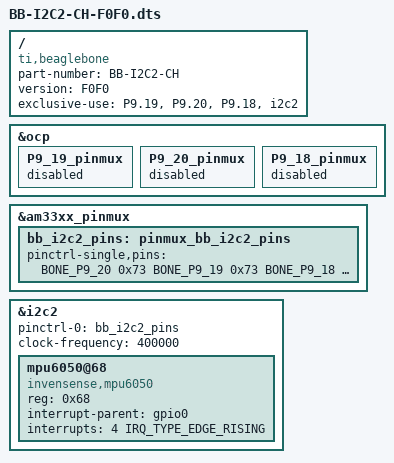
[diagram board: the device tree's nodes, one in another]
/*
 * Copyright (C) 2013 CircuitCo
 *
 * Virtual cape for I2C2 on connector pins P9.19 P9.20
 *
 * This program is free software; you can redistribute it and/or modify
 * it under the terms of the GNU General Public License version 2 as
 * published by the Free Software Foundation.
 */

/dts-v1/;
/plugin/;

#include <dt-bindings/interrupt-controller/irq.h>
#include <dt-bindings/board/am335x-bbw-bbb-base.h>
#include <dt-bindings/pinctrl/am33xx.h>

/ {
	compatible = "ti,beaglebone", "ti,beaglebone-black", "ti,beaglebone-green";

	// identification
	part-number = "BB-I2C2-CH";
	version = "F0F0";

	// resources this cape uses
	exclusive-use =
		"P9.19",	// i2c2_scl
		"P9.20",	// i2c2_sda
		"P9.18",	// int
		
		"i2c2";		// hardware ip used

	/*
	 * Free up the pins used by the cape from the pinmux helpers.
	 */
	fragment@0 {
		target = <&ocp>;
		__overlay__ {
			P9_19_pinmux { status = "disabled"; };	/* i2c2_scl */
			P9_20_pinmux { status = "disabled"; };	/* i2c2_sda */
			P9_18_pinmux { status = "disabled"; };	/*int	*/
		};
	};

	fragment@1 {
		target = <&am33xx_pinmux>;
		__overlay__ {
			bb_i2c2_pins: pinmux_bb_i2c2_pins {
				pinctrl-single,pins = <
					BONE_P9_20 0x73	/* i2c2_sda, SLEWCTRL_SLOW | INPUT_PULLUP | MODE3 */
					BONE_P9_19 0x73	/* i2c2_scl, SLEWCTRL_SLOW | INPUT_PULLUP | MODE3 */
					BONE_P9_18 0x0F	/* INT,		 SLEWCTRL_SLOW | iNPUT_NULL	  | MODE7 */
				>;
			};
		};
	};

	fragment@2 {
		target = <&i2c2>;
		__overlay__ {
			status = "okay";
			pinctrl-names = "default";
			pinctrl-0 = <&bb_i2c2_pins>;

			/* this is the configuration part */
			clock-frequency = <400000>;

			#address-cells = <1>;
			#size-cells = <0>;

			/* add any i2c devices on the bus here */

			mpu6050@68 {
				compatible = "invensense,mpu6050";
				reg = <0x68>;
				interrupt-parent = <&gpio0>;
				interrupts = <4 IRQ_TYPE_EDGE_RISING>;
			};

                        //hmc5883l@1e {
                        //       compatible = "honeywell,hmc5883l";
                        //        reg = <0x1e>;
                        //};
		};
	};
};
